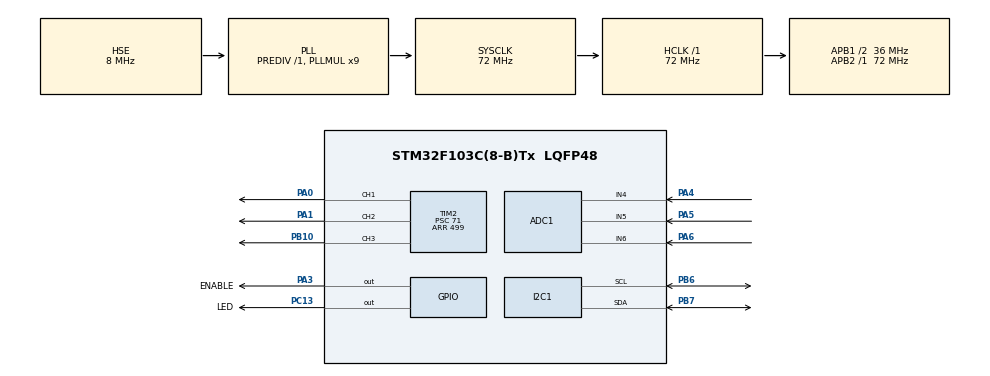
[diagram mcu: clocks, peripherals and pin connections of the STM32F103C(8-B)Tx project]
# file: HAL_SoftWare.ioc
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ADC1.Channel-3\#ChannelRegularConversion=ADC_CHANNEL_5
ADC1.Channel-4\#ChannelRegularConversion=ADC_CHANNEL_4
ADC1.Channel-5\#ChannelRegularConversion=ADC_CHANNEL_6
ADC1.ContinuousConvMode=ENABLE
ADC1.DiscontinuousConvMode=DISABLE
ADC1.NbrOfConversion=3
ADC1.NbrOfConversionFlag=1
ADC1.Rank-3\#ChannelRegularConversion=1
ADC1.Rank-4\#ChannelRegularConversion=2
ADC1.Rank-5\#ChannelRegularConversion=3
ADC1.SamplingTime-3\#ChannelRegularConversion=ADC_SAMPLETIME_1CYCLE_5
ADC1.SamplingTime-4\#ChannelRegularConversion=ADC_SAMPLETIME_1CYCLE_5
ADC1.SamplingTime-5\#ChannelRegularConversion=ADC_SAMPLETIME_1CYCLE_5
ADC1.master=1
Dma.ADC1.0.Direction=DMA_PERIPH_TO_MEMORY
Dma.ADC1.0.Instance=DMA1_Channel1
Dma.ADC1.0.MemDataAlignment=DMA_MDATAALIGN_HALFWORD
Dma.ADC1.0.MemInc=DMA_MINC_ENABLE
Dma.ADC1.0.Mode=DMA_CIRCULAR
Dma.ADC1.0.PeriphDataAlignment=DMA_PDATAALIGN_HALFWORD
Dma.ADC1.0.PeriphInc=DMA_PINC_DISABLE
Dma.ADC1.0.Priority=DMA_PRIORITY_LOW
Dma.Request0=ADC1
Mcu.Family=STM32F1
Mcu.Name=STM32F103C(8-B)Tx
Mcu.Package=LQFP48
NVIC.DMA1_Channel1_IRQn=true\:0\:0\:false\:false\:true\:false\:true\:true
NVIC.PriorityGroup=NVIC_PRIORITYGROUP_4
NVIC.TIM1_UP_IRQn=true\:0\:0\:false\:false\:true\:true\:true\:true
PA0-WKUP.Signal=S_TIM2_CH1_ETR
PA1.Signal=S_TIM2_CH2
PA13.Mode=Serial_Wire
PA13.Signal=SYS_JTMS-SWDIO
PA14.Mode=Serial_Wire
PA14.Signal=SYS_JTCK-SWCLK
PA3.GPIO_Label=ENABLE
PA3.Signal=GPIO_Output
PA4.Signal=SharedAnalog_PA4
PA5.Signal=SharedAnalog_PA5
PA6.Signal=SharedAnalog_PA6
PB10.Signal=S_TIM2_CH3
PB6.Mode=I2C
PB6.Signal=I2C1_SCL
PB7.Mode=I2C
PB7.Signal=I2C1_SDA
PC13-TAMPER-RTC.GPIO_Label=LED
PC13-TAMPER-RTC.Signal=GPIO_Output
PD0-OSC_IN.Mode=HSE-External-Oscillator
PD0-OSC_IN.Signal=RCC_OSC_IN
PD1-OSC_OUT.Mode=HSE-External-Oscillator
PD1-OSC_OUT.Signal=RCC_OSC_OUT
ProjectManager.HeapSize=0x200
ProjectManager.StackSize=0x400
ProjectManager.TargetToolchain=STM32CubeIDE
RCC.ADCPresc=RCC_ADCPCLK2_DIV6
RCC.AHBFreq_Value=72000000
RCC.APB1CLKDivider=RCC_HCLK_DIV2
RCC.APB1Freq_Value=36000000
RCC.APB1TimFreq_Value=72000000
RCC.APB2Freq_Value=72000000
RCC.APB2TimFreq_Value=72000000
RCC.HCLKFreq_Value=72000000
RCC.PLLMUL=RCC_PLL_MUL9
RCC.PLLSourceVirtual=RCC_PLLSOURCE_HSE
RCC.SYSCLKFreq_VALUE=72000000
RCC.SYSCLKSource=RCC_SYSCLKSOURCE_PLLCLK
RCC.USBFreq_Value=72000000
SH.S_TIM2_CH1_ETR.0=TIM2_CH1,PWM Generation1 CH1
SH.S_TIM2_CH2.0=TIM2_CH2,PWM Generation2 CH2
SH.S_TIM2_CH3.0=TIM2_CH3,PWM Generation3 CH3
SH.SharedAnalog_PA4.0=GPIO_Analog
SH.SharedAnalog_PA4.1=ADC1_IN4,IN4
SH.SharedAnalog_PA5.0=GPIO_Analog
SH.SharedAnalog_PA5.1=ADC1_IN5,IN5
SH.SharedAnalog_PA6.0=GPIO_Analog
SH.SharedAnalog_PA6.1=ADC1_IN6,IN6
TIM1.AutoReloadPreload=TIM_AUTORELOAD_PRELOAD_DISABLE
TIM1.CounterMode=TIM_COUNTERMODE_CENTERALIGNED1
TIM1.Period=499
TIM1.Prescaler=71
TIM2.Channel-PWM\ Generation1\ CH1=TIM_CHANNEL_1
TIM2.Channel-PWM\ Generation2\ CH2=TIM_CHANNEL_2
TIM2.Channel-PWM\ Generation3\ CH3=TIM_CHANNEL_3
TIM2.CounterMode=TIM_COUNTERMODE_CENTERALIGNED1
TIM2.Period=499
TIM2.Prescaler=71
VP_TIM1_VS_ClockSourceINT.Mode=Internal
board=custom

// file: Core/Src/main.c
/* USER CODE BEGIN Header */
/**
  ******************************************************************************
  * @file           : main.c
  * @brief          : Main program body
  ******************************************************************************
  * @attention
  *
  * Copyright (c) 2024 STMicroelectronics.
  * All rights reserved.
  *
  * This software is licensed under terms that can be found in the LICENSE file
  * in the root directory of this software component.
  * If no LICENSE file comes with this software, it is provided AS-IS.
  *
  ******************************************************************************
  */
/* USER CODE END Header */
#include "main.h"
#include "adc.h"
#include "dma.h"
#include "i2c.h"
#include "tim.h"
#include "gpio.h"

/* USER CODE BEGIN Includes */
#include "as5600.h"
#include "current.h"
#include "motor.h"
/* USER CODE END Includes */

void SystemClock_Config(void);

int main(void)
{

  /* MCU Configuration--------------------------------------------------------*/

  /* Reset of all peripherals, Initializes the Flash interface and the Systick. */
  HAL_Init();

  /* Configure the system clock */
  SystemClock_Config();

  /* Initialize all configured peripherals */
  MX_GPIO_Init();
  MX_DMA_Init();
  MX_I2C1_Init();
  MX_ADC1_Init();
  MX_TIM1_Init();
  MX_TIM2_Init();
  /* USER CODE BEGIN 2 */
  HAL_ADCEx_Calibration_Start(&hadc1);
  Motor_Init();
  HAL_TIM_Base_Start_IT(&htim1);
  /* USER CODE END 2 */

  /* Infinite loop */
  /* USER CODE BEGIN WHILE */
  while (1)
  {
      HAL_Delay(300);
      HAL_GPIO_TogglePin(LED_GPIO_Port, LED_Pin);
      current_collection();

    /* USER CODE END WHILE */

  }
}

void SystemClock_Config(void)
{
  RCC_OscInitTypeDef RCC_OscInitStruct = {0};
  RCC_ClkInitTypeDef RCC_ClkInitStruct = {0};
  RCC_PeriphCLKInitTypeDef PeriphClkInit = {0};

  /** Initializes the RCC Oscillators according to the specified parameters
  * in the RCC_OscInitTypeDef structure.
  */
  RCC_OscInitStruct.OscillatorType = RCC_OSCILLATORTYPE_HSE;
  RCC_OscInitStruct.HSEState = RCC_HSE_ON;
  RCC_OscInitStruct.HSEPredivValue = RCC_HSE_PREDIV_DIV1;
  RCC_OscInitStruct.HSIState = RCC_HSI_ON;
  RCC_OscInitStruct.PLL.PLLState = RCC_PLL_ON;
  RCC_OscInitStruct.PLL.PLLSource = RCC_PLLSOURCE_HSE;
  RCC_OscInitStruct.PLL.PLLMUL = RCC_PLL_MUL9;
  if (HAL_RCC_OscConfig(&RCC_OscInitStruct) != HAL_OK)
  {
    Error_Handler();
  }

  /** Initializes the CPU, AHB and APB buses clocks
  */
  RCC_ClkInitStruct.ClockType = RCC_CLOCKTYPE_HCLK|RCC_CLOCKTYPE_SYSCLK
                              |RCC_CLOCKTYPE_PCLK1|RCC_CLOCKTYPE_PCLK2;
  RCC_ClkInitStruct.SYSCLKSource = RCC_SYSCLKSOURCE_PLLCLK;
  RCC_ClkInitStruct.AHBCLKDivider = RCC_SYSCLK_DIV1;
  RCC_ClkInitStruct.APB1CLKDivider = RCC_HCLK_DIV2;
  RCC_ClkInitStruct.APB2CLKDivider = RCC_HCLK_DIV1;

  if (HAL_RCC_ClockConfig(&RCC_ClkInitStruct, FLASH_LATENCY_2) != HAL_OK)
  {
    Error_Handler();
  }
  PeriphClkInit.PeriphClockSelection = RCC_PERIPHCLK_ADC;
  PeriphClkInit.AdcClockSelection = RCC_ADCPCLK2_DIV6;
  if (HAL_RCCEx_PeriphCLKConfig(&PeriphClkInit) != HAL_OK)
  {
    Error_Handler();
  }
}

void Error_Handler(void)
{
  __disable_irq();
  while (1)
  {
  }
}
